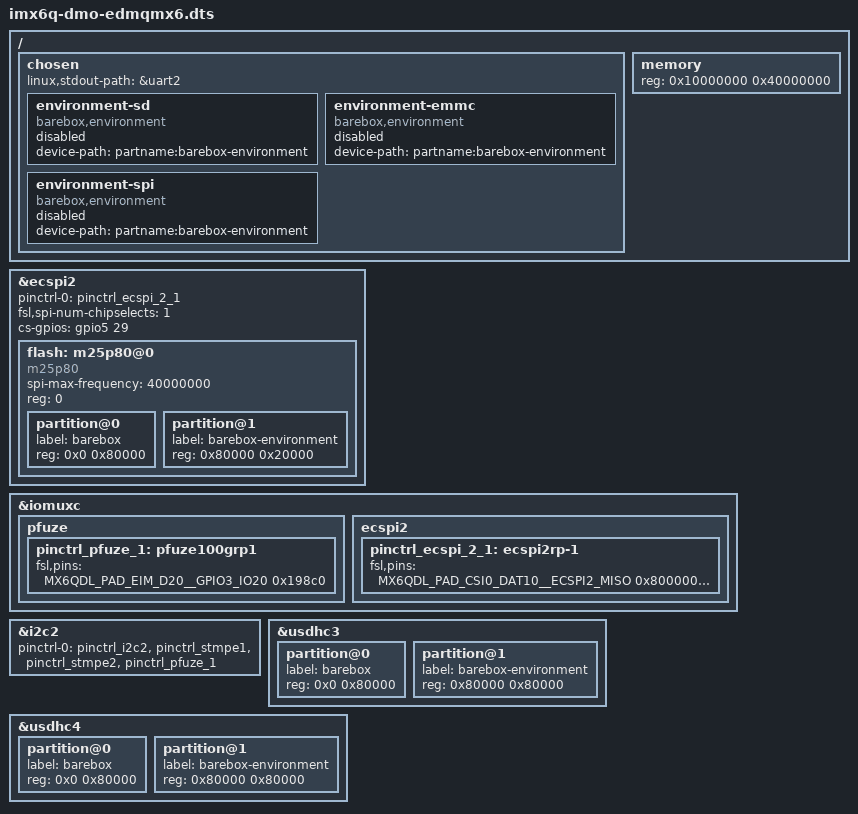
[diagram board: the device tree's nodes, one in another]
/*
 * Copyright 2011 Freescale Semiconductor, Inc.
 * Copyright 2011 Linaro Ltd.
 * Copyright 2013-2014 Data-Modul AG
 *
 * The code contained herein is licensed under the GNU General Public
 * License. You may obtain a copy of the GNU General Public License
 * Version 2 or later at the following locations:
 *
 * http://www.opensource.org/licenses/gpl-license.html
 * http://www.gnu.org/copyleft/gpl.html
 */

#include <arm/imx6q-dmo-edmqmx6.dts>

/ {
	chosen {
		linux,stdout-path = &uart2;

		environment-sd {
			compatible = "barebox,environment";
			device-path = &usdhc3, "partname:barebox-environment";
			status = "disabled";
		};

		environment-emmc {
			compatible = "barebox,environment";
			device-path = &usdhc4, "partname:barebox-environment";
			status = "disabled";
		};

		environment-spi {
			compatible = "barebox,environment";
			device-path = &flash, "partname:barebox-environment";
			status = "disabled";
		};
	};

	memory {
		reg = <0x10000000 0x40000000>;
	};
};

&ecspi2 {
	pinctrl-names = "default";
	pinctrl-0 = <&pinctrl_ecspi_2_1>;
	fsl,spi-num-chipselects = <1>;
	cs-gpios = <&gpio5 29 0>;
	status = "okay";

	flash: m25p80@0 {
		compatible = "m25p80";
		spi-max-frequency = <40000000>;
		reg = <0>;
		#address-cells = <1>;
		#size-cells = <1>;

		partition@0 {
			label = "barebox";
			reg = <0x0 0x80000>;
		};

		partition@1 {
			label = "barebox-environment";
			reg = <0x80000 0x20000>;
		};
	};
};

&iomuxc {
	pfuze {
		pinctrl_pfuze_1: pfuze100grp1 {
			fsl,pins = <
				MX6QDL_PAD_EIM_D20__GPIO3_IO20 0x198c0
			>;
		};
	};

	ecspi2 {
		pinctrl_ecspi_2_1: ecspi2rp-1 {
			fsl,pins = <
				MX6QDL_PAD_CSI0_DAT10__ECSPI2_MISO	0x80000000
				MX6QDL_PAD_CSI0_DAT9__ECSPI2_MOSI	0x80000000
				MX6QDL_PAD_CSI0_DAT8__ECSPI2_SCLK	0x80000000
				/* CS */
				MX6QDL_PAD_CSI0_DAT11__GPIO5_IO29	0x80000000
			>;
		};
	};
};

&i2c2 {
	pinctrl-0 = <&pinctrl_i2c2
	             &pinctrl_stmpe1
	             &pinctrl_stmpe2
	             &pinctrl_pfuze_1>;
};

&usdhc3 {
	#address-cells = <1>;
	#size-cells = <1>;

	partition@0 {
		label = "barebox";
		reg = <0x0 0x80000>;
	};
	partition@1 {
		label = "barebox-environment";
		reg = <0x80000 0x80000>;
	};
};

&usdhc4 {
	#address-cells = <1>;
	#size-cells = <1>;

	partition@0 {
		label = "barebox";
		reg = <0x0 0x80000>;
	};
	partition@1 {
		label = "barebox-environment";
		reg = <0x80000 0x80000>;
	};
};
